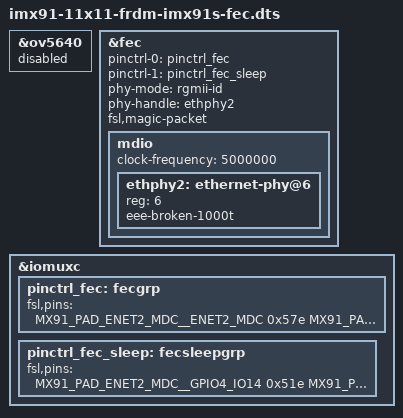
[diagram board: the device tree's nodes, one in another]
// SPDX-License-Identifier: (GPL-2.0+ OR MIT)
/*
 * Copyright 2025 NXP
 */

#include "imx91-11x11-frdm-imx91s.dts"

/ {

};

&ov5640 {
	status = "disabled";
};

&fec {
	pinctrl-names = "default", "sleep";
	pinctrl-0 = <&pinctrl_fec>;
	pinctrl-1 = <&pinctrl_fec_sleep>;
	phy-mode = "rgmii-id";
	phy-handle = <&ethphy2>;
	fsl,magic-packet;
	status = "okay";

	mdio {
		#address-cells = <1>;
		#size-cells = <0>;
		clock-frequency = <5000000>;

		ethphy2: ethernet-phy@6 {
			reg = <6>;
			eee-broken-1000t;
		};
	};
};

&iomuxc {
	pinctrl_fec: fecgrp {
		fsl,pins = <
			MX91_PAD_ENET2_MDC__ENET2_MDC			0x57e
			MX91_PAD_ENET2_MDIO__ENET2_MDIO			0x57e
			MX91_PAD_ENET2_RD0__ENET2_RGMII_RD0		0x57e
			MX91_PAD_ENET2_RD1__ENET2_RGMII_RD1		0x57e
			MX91_PAD_ENET2_RD2__ENET2_RGMII_RD2		0x57e
			MX91_PAD_ENET2_RD3__ENET2_RGMII_RD3		0x57e
			MX91_PAD_ENET2_RXC__ENET2_RGMII_RXC		0x5fe
			MX91_PAD_ENET2_RX_CTL__ENET2_RGMII_RX_CTL	0x57e
			MX91_PAD_ENET2_TD0__ENET2_RGMII_TD0		0x57e
			MX91_PAD_ENET2_TD1__ENET2_RGMII_TD1		0x57e
			MX91_PAD_ENET2_TD2__ENET2_RGMII_TD2		0x57e
			MX91_PAD_ENET2_TD3__ENET2_RGMII_TD3		0x57e
			MX91_PAD_ENET2_TXC__ENET2_RGMII_TXC		0x5fe
			MX91_PAD_ENET2_TX_CTL__ENET2_RGMII_TX_CTL	0x57e
		>;
	};

	pinctrl_fec_sleep: fecsleepgrp {
		fsl,pins = <
			MX91_PAD_ENET2_MDC__GPIO4_IO14			0x51e
			MX91_PAD_ENET2_MDIO__GPIO4_IO15			0x51e
			MX91_PAD_ENET2_RD0__GPIO4_IO24			0x51e
			MX91_PAD_ENET2_RD1__GPIO4_IO25			0x51e
			MX91_PAD_ENET2_RD2__GPIO4_IO26			0x51e
			MX91_PAD_ENET2_RD3__GPIO4_IO27			0x51e
			MX91_PAD_ENET2_RXC__GPIO4_IO23                  0x51e
			MX91_PAD_ENET2_RX_CTL__GPIO4_IO22		0x51e
			MX91_PAD_ENET2_TD0__GPIO4_IO19			0x51e
			MX91_PAD_ENET2_TD1__GPIO4_IO18			0x51e
			MX91_PAD_ENET2_TD2__GPIO4_IO17			0x51e
			MX91_PAD_ENET2_TD3__GPIO4_IO16			0x51e
			MX91_PAD_ENET2_TXC__GPIO4_IO21                  0x51e
			MX91_PAD_ENET2_TX_CTL__GPIO4_IO20               0x51e
		>;
	};
};
